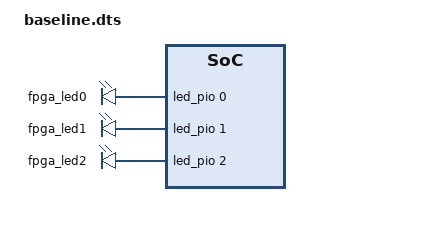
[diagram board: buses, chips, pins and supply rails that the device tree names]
// SPDX-License-Identifier: GPL-2.0-only
/*
 * Copyright (C) 2025, Altera Corporation
 */
/dts-v1/;
#include "socfpga_agilex_socdk.dts"

/{
	soc {

		led_pio: gpio@f9001080 {
				compatible = "altr,pio-1.0";
				reg = <0xf9001080 0x8>;
				altr,gpio-bank-width = <4>;
				#gpio-cells = <2>;
				gpio-controller;
				resetvalue = <0>;
		};

		trigger_pio: gpio@f9001040 {
				compatible = "altr,pio-1.0";
				reg = <0xf9001040 0x20>;
				altr,gpio-bank-width = <4>;
				#gpio-cells = <2>;
				gpio-controller;
				resetvalue = <0>;
		};

		soc_leds: leds {
			compatible = "gpio-leds";

			led_fpga0: fpga0 {
					label = "fpga_led0";
					gpios = <&led_pio 0 0>;
			}; //end fpga0 (led_fpga0)

			led_fpga1: fpga1 {
					label = "fpga_led1";
					gpios = <&led_pio 1 0>;
			}; //end fpga1 (led_fpga1)

			led_fpga2: fpga2 {
					label = "fpga_led2";
					gpios = <&led_pio 2 0>;
			}; //end fpga2 (led_fpga2)
		};

	};
};
